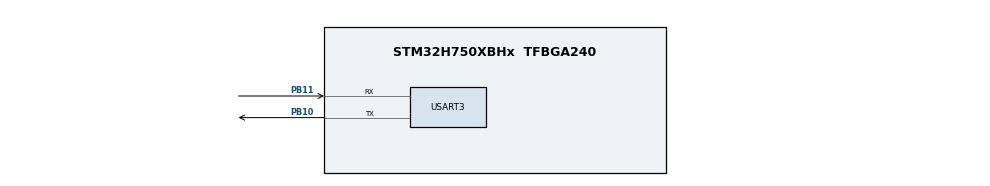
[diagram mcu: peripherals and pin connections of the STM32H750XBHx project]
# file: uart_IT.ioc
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Mcu.Family=STM32H7
Mcu.Name=STM32H750XBHx
Mcu.Package=TFBGA240
NVIC.PriorityGroup=NVIC_PRIORITYGROUP_4
NVIC.USART3_IRQn=true\:0\:0\:false\:false\:true\:true\:true\:true
PB10.Mode=Asynchronous
PB10.Signal=USART3_TX
PB11.Mode=Asynchronous
PB11.Signal=USART3_RX
ProjectManager.HeapSize=0x200
ProjectManager.StackSize=0x400
ProjectManager.TargetToolchain=STM32CubeIDE
RCC.ADCFreq_Value=76800000
RCC.APB1Freq_Value=64000000
RCC.APB2Freq_Value=64000000
RCC.APB3Freq_Value=64000000
RCC.APB4Freq_Value=64000000
RCC.CortexFreq_Value=64000000
RCC.DIVM1=22
RCC.DIVM2=2
RCC.DIVN1=169
RCC.DIVN2=12
RCC.DIVN3=192
RCC.DIVP2=5
RCC.DIVQ1=4
RCC.HCLKFreq_Value=64000000
RCC.PLL2FRACN=0
RCC.PLL3FRACN=0
RCC.PLLFRACN=0
RCC.PWR_Regulator_Voltage_Scale=PWR_REGULATOR_VOLTAGE_SCALE2
RCC.SYSCLKFreq_VALUE=64000000
RCC.USBFreq_Value=122909090.9090909
USART3.VirtualMode-Asynchronous=VM_ASYNC
board=STM32H750B-DK

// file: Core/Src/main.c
/* USER CODE BEGIN Header */
/**
  ******************************************************************************
  * @file           : main.c
  * @brief          : Main program body
  ******************************************************************************
  * @attention
  *
  * Copyright (c) 2023 STMicroelectronics.
  * All rights reserved.
  *
  * This software is licensed under terms that can be found in the LICENSE file
  * in the root directory of this software component.
  * If no LICENSE file comes with this software, it is provided AS-IS.
  *
  ******************************************************************************
  */
/* USER CODE END Header */
#include "main.h"

/* USER CODE BEGIN Includes */
#include <string.h>
/* USER CODE END Includes */

UART_HandleTypeDef huart3;

/* USER CODE BEGIN PV */
uint8_t buffer1[] = {"Swapped to buffer1!\n"};
uint8_t buffer2[] = {"Swapped to buffer2!\n"};
/* USER CODE END PV */

void SystemClock_Config(void);
static void MX_GPIO_Init(void);
static void MX_USART3_UART_Init(void);
/* USER CODE BEGIN PFP */
void HAL_UART_TxCpltCallback(UART_HandleTypeDef *huart);
/* USER CODE END PFP */

int main(void)
{

  /* MCU Configuration--------------------------------------------------------*/

  /* Reset of all peripherals, Initializes the Flash interface and the Systick. */
  HAL_Init();

  /* Configure the system clock */
  SystemClock_Config();

  /* Initialize all configured peripherals */
  MX_GPIO_Init();
  MX_USART3_UART_Init();

  /* Infinite loop */
  while (1)
  {

  }
}

void SystemClock_Config(void)
{
  RCC_OscInitTypeDef RCC_OscInitStruct = {0};
  RCC_ClkInitTypeDef RCC_ClkInitStruct = {0};

  /** Supply configuration update enable
  */
  HAL_PWREx_ConfigSupply(PWR_LDO_SUPPLY);

  /** Configure the main internal regulator output voltage
  */
  __HAL_PWR_VOLTAGESCALING_CONFIG(PWR_REGULATOR_VOLTAGE_SCALE2);

  while(!__HAL_PWR_GET_FLAG(PWR_FLAG_VOSRDY)) {}

  /** Initializes the RCC Oscillators according to the specified parameters
  * in the RCC_OscInitTypeDef structure.
  */
  RCC_OscInitStruct.OscillatorType = RCC_OSCILLATORTYPE_HSI;
  RCC_OscInitStruct.HSIState = RCC_HSI_DIV1;
  RCC_OscInitStruct.HSICalibrationValue = RCC_HSICALIBRATION_DEFAULT;
  RCC_OscInitStruct.PLL.PLLState = RCC_PLL_NONE;
  if (HAL_RCC_OscConfig(&RCC_OscInitStruct) != HAL_OK)
  {
    Error_Handler();
  }

  /** Initializes the CPU, AHB and APB buses clocks
  */
  RCC_ClkInitStruct.ClockType = RCC_CLOCKTYPE_HCLK|RCC_CLOCKTYPE_SYSCLK
                              |RCC_CLOCKTYPE_PCLK1|RCC_CLOCKTYPE_PCLK2
                              |RCC_CLOCKTYPE_D3PCLK1|RCC_CLOCKTYPE_D1PCLK1;
  RCC_ClkInitStruct.SYSCLKSource = RCC_SYSCLKSOURCE_HSI;
  RCC_ClkInitStruct.SYSCLKDivider = RCC_SYSCLK_DIV1;
  RCC_ClkInitStruct.AHBCLKDivider = RCC_HCLK_DIV1;
  RCC_ClkInitStruct.APB3CLKDivider = RCC_APB3_DIV1;
  RCC_ClkInitStruct.APB1CLKDivider = RCC_APB1_DIV1;
  RCC_ClkInitStruct.APB2CLKDivider = RCC_APB2_DIV1;
  RCC_ClkInitStruct.APB4CLKDivider = RCC_APB4_DIV1;

  if (HAL_RCC_ClockConfig(&RCC_ClkInitStruct, FLASH_LATENCY_1) != HAL_OK)
  {
    Error_Handler();
  }
}

static void MX_USART3_UART_Init(void)
{

  huart3.Instance = USART3;
  huart3.Init.BaudRate = 115200;
  huart3.Init.WordLength = UART_WORDLENGTH_8B;
  huart3.Init.StopBits = UART_STOPBITS_1;
  huart3.Init.Parity = UART_PARITY_NONE;
  huart3.Init.Mode = UART_MODE_TX_RX;
  huart3.Init.HwFlowCtl = UART_HWCONTROL_NONE;
  huart3.Init.OverSampling = UART_OVERSAMPLING_16;
  huart3.Init.OneBitSampling = UART_ONE_BIT_SAMPLE_DISABLE;
  huart3.Init.ClockPrescaler = UART_PRESCALER_DIV1;
  huart3.AdvancedInit.AdvFeatureInit = UART_ADVFEATURE_NO_INIT;
  if (HAL_UART_Init(&huart3) != HAL_OK)
  {
    Error_Handler();
  }
  if (HAL_UARTEx_SetTxFifoThreshold(&huart3, UART_TXFIFO_THRESHOLD_1_8) != HAL_OK)
  {
    Error_Handler();
  }
  if (HAL_UARTEx_SetRxFifoThreshold(&huart3, UART_RXFIFO_THRESHOLD_1_8) != HAL_OK)
  {
    Error_Handler();
  }
  if (HAL_UARTEx_DisableFifoMode(&huart3) != HAL_OK)
  {
    Error_Handler();
  }
  /* USER CODE BEGIN USART3_Init 2 */
  HAL_UART_Transmit_IT(&huart3, buffer1, strlen((char*)buffer1));
  __HAL_UART_ENABLE_IT(&huart3, UART_IT_TXE);
  /* USER CODE END USART3_Init 2 */

}

static void MX_GPIO_Init(void)
{

  /* GPIO Ports Clock Enable */
  __HAL_RCC_GPIOB_CLK_ENABLE();

}

/* USER CODE BEGIN 4 */
void HAL_UART_TxCpltCallback(UART_HandleTypeDef *huart){//called on transmit end
	if(huart->pTxBuffPtr == &buffer1[strlen((char*)buffer1)])
		HAL_UART_Transmit_IT(&huart3, buffer2, strlen((char*)buffer2));
	else
		HAL_UART_Transmit_IT(&huart3, buffer1, strlen((char*)buffer1));
	return;

}
/* USER CODE END 4 */

void Error_Handler(void)
{
  __disable_irq();
  while (1)
  {
  }
}
